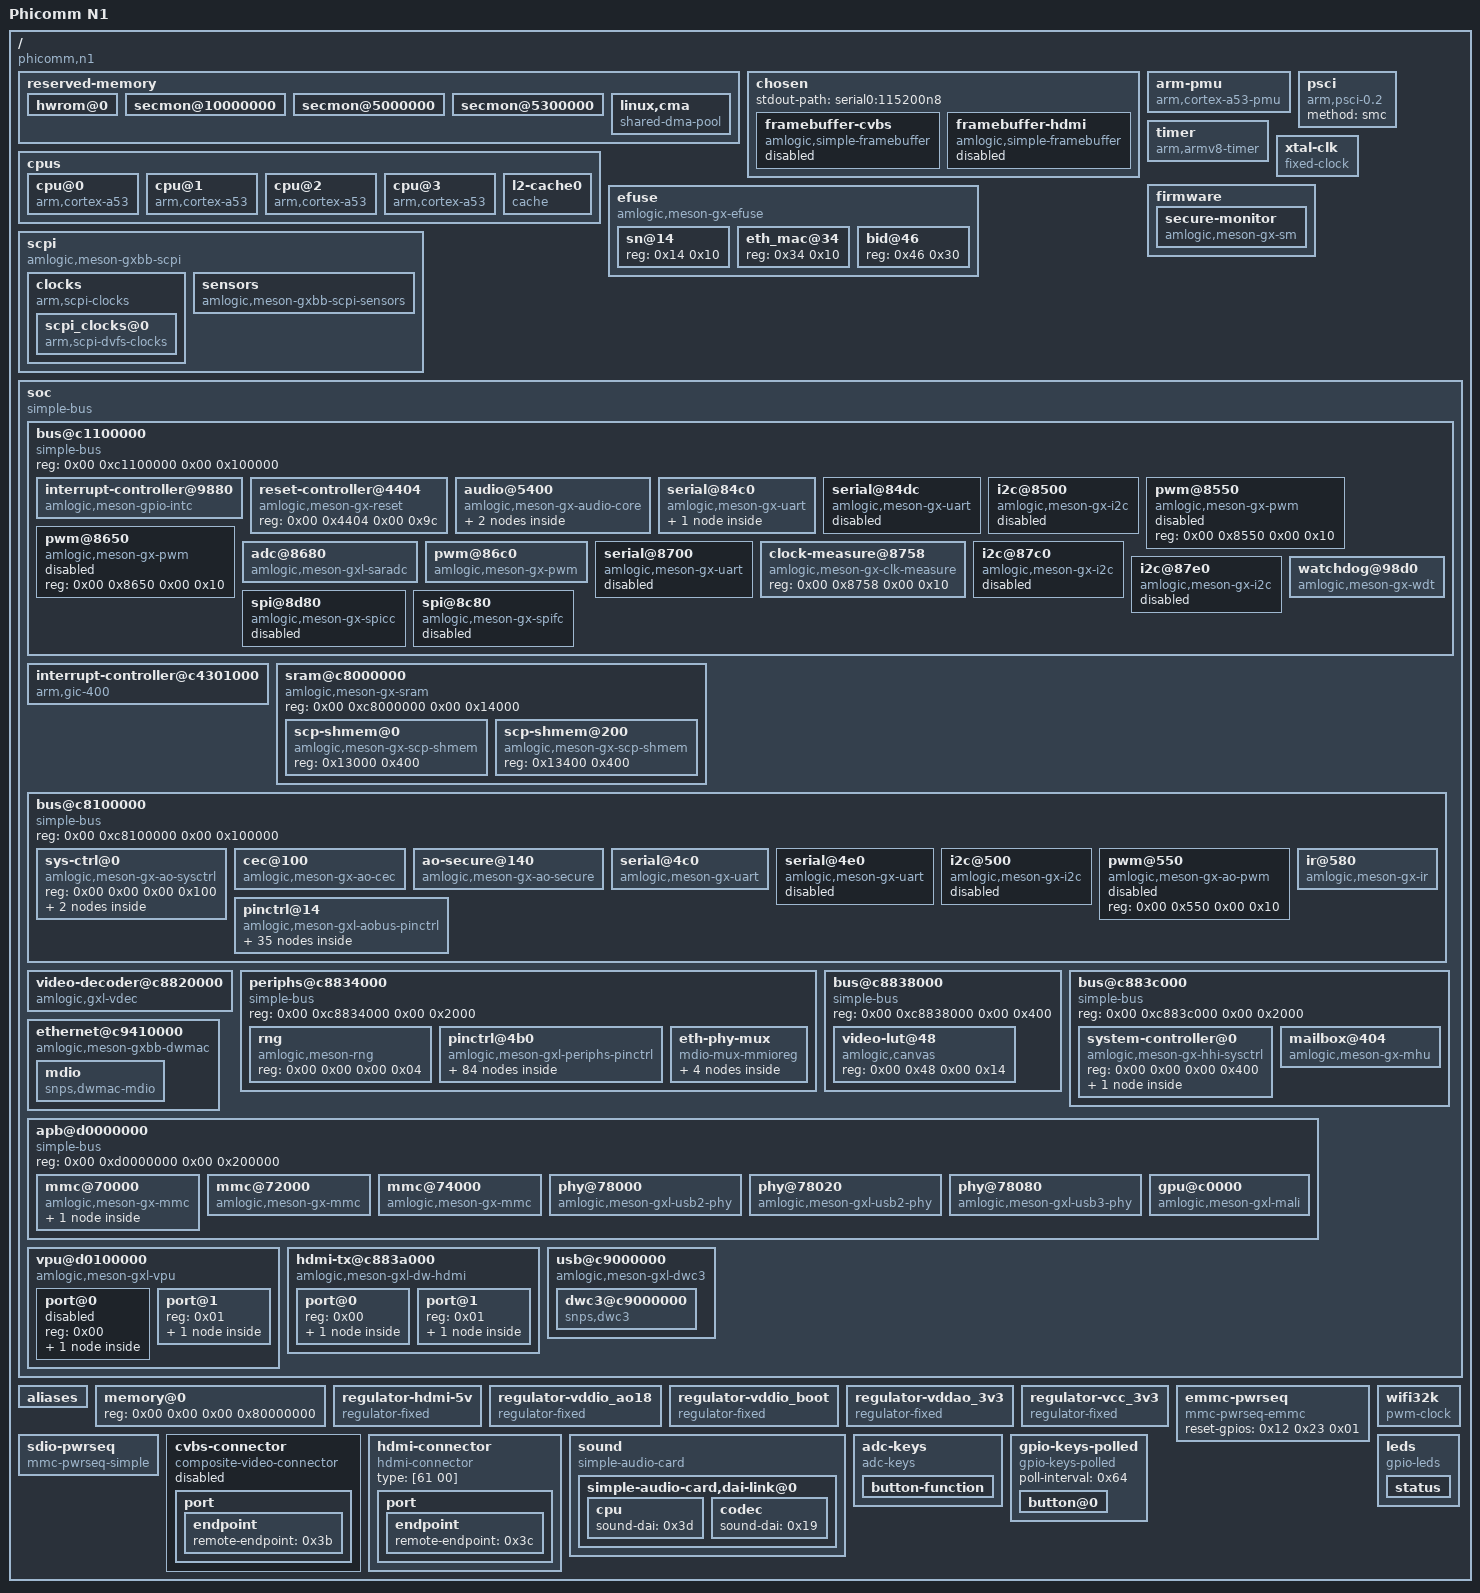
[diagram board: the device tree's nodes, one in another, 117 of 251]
/dts-v1/;

/ {
	interrupt-parent = <0x01>;
	#address-cells = <0x02>;
	#size-cells = <0x02>;
	compatible = "phicomm,n1\0amlogic,s905d\0amlogic,meson-gxl";
	model = "Phicomm N1";

	reserved-memory {
		#address-cells = <0x02>;
		#size-cells = <0x02>;
		ranges;

		hwrom@0 {
			reg = <0x00 0x00 0x00 0x1000000>;
			no-map;
		};

		secmon@10000000 {
			reg = <0x00 0x10000000 0x00 0x200000>;
			no-map;
		};

		secmon@5000000 {
			reg = <0x00 0x5000000 0x00 0x300000>;
			no-map;
		};

		secmon@5300000 {
			reg = <0x00 0x5300000 0x00 0x2000000>;
			no-map;
		};

		linux,cma {
			compatible = "shared-dma-pool";
			reusable;
			size = <0x00 0x38000000>;
			alignment = <0x00 0x400000>;
			linux,cma-default;
		};
	};

	chosen {
		#address-cells = <0x02>;
		#size-cells = <0x02>;
		ranges;
		stdout-path = "serial0:115200n8";

		framebuffer-cvbs {
			compatible = "amlogic,simple-framebuffer\0simple-framebuffer";
			amlogic,pipeline = "vpu-cvbs";
			power-domains = <0x02>;
			status = "disabled";
		};

		framebuffer-hdmi {
			compatible = "amlogic,simple-framebuffer\0simple-framebuffer";
			amlogic,pipeline = "vpu-hdmi";
			power-domains = <0x02>;
			status = "disabled";
			clocks = <0x03 0x3f 0x03 0x0c 0x03 0x4d>;
		};
	};

	cpus {
		#address-cells = <0x02>;
		#size-cells = <0x00>;

		cpu@0 {
			device_type = "cpu";
			compatible = "arm,cortex-a53";
			reg = <0x00 0x00>;
			enable-method = "psci";
			next-level-cache = <0x04>;
			clocks = <0x05 0x00>;
			phandle = <0x06>;
		};

		cpu@1 {
			device_type = "cpu";
			compatible = "arm,cortex-a53";
			reg = <0x00 0x01>;
			enable-method = "psci";
			next-level-cache = <0x04>;
			clocks = <0x05 0x00>;
			phandle = <0x07>;
		};

		cpu@2 {
			device_type = "cpu";
			compatible = "arm,cortex-a53";
			reg = <0x00 0x02>;
			enable-method = "psci";
			next-level-cache = <0x04>;
			clocks = <0x05 0x00>;
			phandle = <0x08>;
		};

		cpu@3 {
			device_type = "cpu";
			compatible = "arm,cortex-a53";
			reg = <0x00 0x03>;
			enable-method = "psci";
			next-level-cache = <0x04>;
			clocks = <0x05 0x00>;
			phandle = <0x09>;
		};

		l2-cache0 {
			compatible = "cache";
			phandle = <0x04>;
		};
	};

	arm-pmu {
		compatible = "arm,cortex-a53-pmu";
		interrupts = <0x00 0x89 0x04 0x00 0x8a 0x04 0x00 0x99 0x04 0x00 0x9a 0x04>;
		interrupt-affinity = <0x06 0x07 0x08 0x09>;
	};

	psci {
		compatible = "arm,psci-0.2";
		method = "smc";
	};

	timer {
		compatible = "arm,armv8-timer";
		interrupts = <0x01 0x0d 0xff08 0x01 0x0e 0xff08 0x01 0x0b 0xff08 0x01 0x0a 0xff08>;
	};

	xtal-clk {
		compatible = "fixed-clock";
		clock-frequency = <0x16e3600>;
		clock-output-names = "xtal";
		#clock-cells = <0x00>;
		phandle = <0x0f>;
	};

	firmware {

		secure-monitor {
			compatible = "amlogic,meson-gx-sm\0amlogic,meson-gxbb-sm";
			phandle = <0x0a>;
		};
	};

	efuse {
		compatible = "amlogic,meson-gx-efuse\0amlogic,meson-gxbb-efuse";
		#address-cells = <0x01>;
		#size-cells = <0x01>;
		read-only;
		secure-monitor = <0x0a>;
		clocks = <0x03 0x3a>;

		sn@14 {
			reg = <0x14 0x10>;
		};

		eth_mac@34 {
			reg = <0x34 0x10>;
		};

		bid@46 {
			reg = <0x46 0x30>;
		};
	};

	scpi {
		compatible = "amlogic,meson-gxbb-scpi\0arm,scpi-pre-1.0";
		mboxes = <0x0b 0x01 0x0b 0x02>;
		shmem = <0x0c 0x0d>;

		clocks {
			compatible = "arm,scpi-clocks";

			scpi_clocks@0 {
				compatible = "arm,scpi-dvfs-clocks";
				#clock-cells = <0x01>;
				clock-indices = <0x00>;
				clock-output-names = "vcpu";
				phandle = <0x05>;
			};
		};

		sensors {
			compatible = "amlogic,meson-gxbb-scpi-sensors\0arm,scpi-sensors";
			#thermal-sensor-cells = <0x01>;
		};
	};

	soc {
		compatible = "simple-bus";
		#address-cells = <0x02>;
		#size-cells = <0x02>;
		ranges;

		bus@c1100000 {
			compatible = "simple-bus";
			reg = <0x00 0xc1100000 0x00 0x100000>;
			#address-cells = <0x02>;
			#size-cells = <0x02>;
			ranges = <0x00 0x00 0x00 0xc1100000 0x00 0x100000>;

			interrupt-controller@9880 {
				compatible = "amlogic,meson-gpio-intc\0amlogic,meson-gxl-gpio-intc";
				reg = <0x00 0x9880 0x00 0x10>;
				interrupt-controller;
				#interrupt-cells = <0x02>;
				amlogic,channel-interrupts = <0x40 0x41 0x42 0x43 0x44 0x45 0x46 0x47>;
				status = "okay";
				#phandle = <0x21>;
			};

			reset-controller@4404 {
				compatible = "amlogic,meson-gx-reset\0amlogic,meson-gxbb-reset";
				reg = <0x00 0x4404 0x00 0x9c>;
				#reset-cells = <0x01>;
				phandle = <0x0e>;
			};

			audio@5400 {
				compatible = "amlogic,meson-gx-audio-core";
				reg = <0x00 0x5400 0x00 0x2ac 0x00 0xa000 0x00 0x304>;
				reg-names = "aiu\0audin";
				status = "okay";
				clocks = <0x03 0x2f 0x03 0x26 0x03 0x23>;
				clock-names = "aiu_top\0aiu_glue\0audin";
				resets = <0x0e 0x06 0x0e 0x41>;
				reset-names = "aiu\0audin";

				audio-controller-0 {
					#sound-dai-cells = <0x00>;
					compatible = "amlogic,meson-aiu-i2s";
					interrupts = <0x00 0x30 0x01>;
					status = "okay";
					clocks = <0x03 0x28 0x03 0x2c 0x03 0x50 0x03 0x6b>;
					clock-names = "fast\0iface\0bclks\0mclk";
					phandle = <0x3d>;
				};

				audio-controller-1 {
					#sound-dai-cells = <0x00>;
					compatible = "amlogic,meson-aiu-spdif";
					interrupts = <0x00 0x32 0x01>;
					status = "disabled";
					clocks = <0x03 0x27 0x03 0x51 0x03 0x6e 0x03 0x6b 0x03 0x71>;
					clock-names = "fast\0iface\0mclk_i958\0mclk_i2s\0mclk";
				};
			};

			serial@84c0 {
				compatible = "amlogic,meson-gx-uart";
				reg = <0x00 0x84c0 0x00 0x18>;
				interrupts = <0x00 0x1a 0x01>;
				status = "okay";
				clocks = <0x0f 0x03 0x1a 0x0f>;
				clock-names = "xtal\0pclk\0baud";
				pinctrl-0 = <0x10 0x11>;
				pinctrl-names = "default";
				uart-has-rtscts;

				bluetooth {
					compatible = "brcm,bcm43438-bt";
					shutdown-gpios = <0x12 0x60 0x00>;
					max-speed = <0x1e8480>;
					clocks = <0x13>;
					clock-names = "lpo";
				};
			};

			serial@84dc {
				compatible = "amlogic,meson-gx-uart";
				reg = <0x00 0x84dc 0x00 0x18>;
				interrupts = <0x00 0x4b 0x01>;
				status = "disabled";
				clocks = <0x0f 0x03 0x30 0x0f>;
				clock-names = "xtal\0pclk\0baud";
			};

			i2c@8500 {
				compatible = "amlogic,meson-gx-i2c\0amlogic,meson-gxbb-i2c";
				reg = <0x00 0x8500 0x00 0x20>;
				interrupts = <0x00 0x15 0x01>;
				#address-cells = <0x01>;
				#size-cells = <0x00>;
				status = "disabled";
				clocks = <0x03 0x16>;
			};

			pwm@8550 {
				compatible = "amlogic,meson-gx-pwm\0amlogic,meson-gxbb-pwm";
				reg = <0x00 0x8550 0x00 0x10>;
				#pwm-cells = <0x03>;
				status = "disabled";
			};

			pwm@8650 {
				compatible = "amlogic,meson-gx-pwm\0amlogic,meson-gxbb-pwm";
				reg = <0x00 0x8650 0x00 0x10>;
				#pwm-cells = <0x03>;
				status = "disabled";
			};

			adc@8680 {
				compatible = "amlogic,meson-gxl-saradc\0amlogic,meson-saradc";
				reg = <0x00 0x8680 0x00 0x34>;
				#io-channel-cells = <0x01>;
				interrupts = <0x00 0x49 0x01>;
				status = "okay";
				clocks = <0x0f 0x03 0x17 0x03 0x61 0x03 0x62>;
				clock-names = "clkin\0core\0adc_clk\0adc_sel";
				vref-supply = <0x14>;
				phandle = <0x3e>;
			};

			pwm@86c0 {
				compatible = "amlogic,meson-gx-pwm\0amlogic,meson-gxbb-pwm";
				reg = <0x00 0x86c0 0x00 0x10>;
				#pwm-cells = <0x03>;
				status = "okay";
				pinctrl-0 = <0x15>;
				pinctrl-names = "default";
				clocks = <0x03 0x06>;
				clock-names = "clkin0";
				phandle = <0x3a>;
			};

			serial@8700 {
				compatible = "amlogic,meson-gx-uart";
				reg = <0x00 0x8700 0x00 0x18>;
				interrupts = <0x00 0x5d 0x01>;
				status = "disabled";
				clocks = <0x0f 0x03 0x44 0x0f>;
				clock-names = "xtal\0pclk\0baud";
			};

			clock-measure@8758 {
				compatible = "amlogic,meson-gx-clk-measure";
				reg = <0x00 0x8758 0x00 0x10>;
			};

			i2c@87c0 {
				compatible = "amlogic,meson-gx-i2c\0amlogic,meson-gxbb-i2c";
				reg = <0x00 0x87c0 0x00 0x20>;
				interrupts = <0x00 0xd6 0x01>;
				#address-cells = <0x01>;
				#size-cells = <0x00>;
				status = "disabled";
				clocks = <0x03 0x16>;
			};

			i2c@87e0 {
				compatible = "amlogic,meson-gx-i2c\0amlogic,meson-gxbb-i2c";
				reg = <0x00 0x87e0 0x00 0x20>;
				interrupts = <0x00 0xd7 0x01>;
				#address-cells = <0x01>;
				#size-cells = <0x00>;
				status = "disabled";
				clocks = <0x03 0x16>;
			};

			spi@8d80 {
				compatible = "amlogic,meson-gx-spicc";
				reg = <0x00 0x8d80 0x00 0x80>;
				interrupts = <0x00 0x51 0x04>;
				#address-cells = <0x01>;
				#size-cells = <0x00>;
				status = "disabled";
				clocks = <0x03 0x15>;
				clock-names = "core";
				resets = <0x0e 0xc1>;
				num-cs = <0x01>;
			};

			spi@8c80 {
				compatible = "amlogic,meson-gx-spifc\0amlogic,meson-gxbb-spifc";
				reg = <0x00 0x8c80 0x00 0x80>;
				#address-cells = <0x01>;
				#size-cells = <0x00>;
				status = "disabled";
				clocks = <0x03 0x22>;
			};

			watchdog@98d0 {
				compatible = "amlogic,meson-gx-wdt\0amlogic,meson-gxbb-wdt";
				reg = <0x00 0x98d0 0x00 0x10>;
				clocks = <0x0f>;
			};
		};

		interrupt-controller@c4301000 {
			compatible = "arm,gic-400";
			reg = <0x00 0xc4301000 0x00 0x1000 0x00 0xc4302000 0x00 0x2000 0x00 0xc4304000 0x00 0x2000 0x00 0xc4306000 0x00 0x2000>;
			interrupt-controller;
			interrupts = <0x01 0x09 0xff04>;
			#interrupt-cells = <0x03>;
			#address-cells = <0x00>;
			phandle = <0x01>;
		};

		sram@c8000000 {
			compatible = "amlogic,meson-gx-sram\0amlogic,meson-gxbb-sram\0mmio-sram";
			reg = <0x00 0xc8000000 0x00 0x14000>;
			#address-cells = <0x01>;
			#size-cells = <0x01>;
			ranges = <0x00 0x00 0xc8000000 0x14000>;

			scp-shmem@0 {
				compatible = "amlogic,meson-gx-scp-shmem\0amlogic,meson-gxbb-scp-shmem";
				reg = <0x13000 0x400>;
				phandle = <0x0c>;
			};

			scp-shmem@200 {
				compatible = "amlogic,meson-gx-scp-shmem\0amlogic,meson-gxbb-scp-shmem";
				reg = <0x13400 0x400>;
				phandle = <0x0d>;
			};
		};

		bus@c8100000 {
			compatible = "simple-bus";
			reg = <0x00 0xc8100000 0x00 0x100000>;
			#address-cells = <0x02>;
			#size-cells = <0x02>;
			ranges = <0x00 0x00 0x00 0xc8100000 0x00 0x100000>;

			sys-ctrl@0 {
				compatible = "amlogic,meson-gx-ao-sysctrl\0simple-mfd\0syscon";
				reg = <0x00 0x00 0x00 0x100>;
				phandle = <0x1d>;

				power-controller-vpu {
					compatible = "amlogic,meson-gx-pwrc-vpu";
					#power-domain-cells = <0x00>;
					amlogic,hhi-sysctrl = <0x16>;
					resets = <0x0e 0x05 0x0e 0x0a 0x0e 0x0d 0x0e 0x25 0x0e 0x84 0x0e 0x85 0x0e 0x86 0x0e 0x87 0x0e 0x89 0x0e 0x8c 0x0e 0x8d 0x0e 0xe7>;
					clocks = <0x03 0x84 0x03 0x8c>;
					clock-names = "vpu\0vapb";
					assigned-clocks = <0x03 0x7e 0x03 0x80 0x03 0x84 0x03 0x85 0x03 0x87 0x03 0x8b>;
					assigned-clock-parents = <0x03 0x05 0x00 0x03 0x80 0x03 0x06 0x00 0x03 0x87>;
					assigned-clock-rates = <0x00 0x27bc86aa 0x00 0x00 0xee6b280 0x00>;
					phandle = <0x02>;
				};

				clock-controller {
					compatible = "amlogic,meson-gxl-aoclkc\0amlogic,meson-gx-aoclkc";
					#clock-cells = <0x01>;
					#reset-cells = <0x01>;
					clocks = <0x0f 0x03 0x0c>;
					clock-names = "xtal\0mpeg-clk";
					phandle = <0x17>;
				};
			};

			cec@100 {
				compatible = "amlogic,meson-gx-ao-cec";
				reg = <0x00 0x100 0x00 0x14>;
				interrupts = <0x00 0xc7 0x01>;
				clocks = <0x17 0x06>;
				clock-names = "core";
				status = "okay";
				pinctrl-0 = <0x18>;
				pinctrl-names = "default";
				hdmi-phandle = <0x19>;
			};

			ao-secure@140 {
				compatible = "amlogic,meson-gx-ao-secure\0syscon";
				reg = <0x00 0x140 0x00 0x140>;
				amlogic,has-chip-id;
			};

			serial@4c0 {
				compatible = "amlogic,meson-gx-uart\0amlogic,meson-ao-uart";
				reg = <0x00 0x4c0 0x00 0x18>;
				interrupts = <0x00 0xc1 0x01>;
				status = "okay";
				clocks = <0x0f 0x17 0x03 0x0f>;
				clock-names = "xtal\0pclk\0baud";
				pinctrl-0 = <0x1a>;
				pinctrl-names = "default";
			};

			serial@4e0 {
				compatible = "amlogic,meson-gx-uart\0amlogic,meson-ao-uart";
				reg = <0x00 0x4e0 0x00 0x18>;
				interrupts = <0x00 0xc5 0x01>;
				status = "disabled";
				clocks = <0x0f 0x17 0x04 0x0f>;
				clock-names = "xtal\0pclk\0baud";
			};

			i2c@500 {
				compatible = "amlogic,meson-gx-i2c\0amlogic,meson-gxbb-i2c";
				reg = <0x00 0x500 0x00 0x20>;
				interrupts = <0x00 0xc3 0x01>;
				#address-cells = <0x01>;
				#size-cells = <0x00>;
				status = "disabled";
				clocks = <0x03 0x5d>;
			};

			pwm@550 {
				compatible = "amlogic,meson-gx-ao-pwm\0amlogic,meson-gxbb-ao-pwm";
				reg = <0x00 0x550 0x00 0x10>;
				#pwm-cells = <0x03>;
				status = "disabled";
			};

			ir@580 {
				compatible = "amlogic,meson-gx-ir\0amlogic,meson-gxbb-ir";
				reg = <0x00 0x580 0x00 0x40>;
				interrupts = <0x00 0xc4 0x01>;
				status = "okay";
				pinctrl-0 = <0x1b>;
				pinctrl-names = "default";
				linux,rc-map-name = "rc-geekbox";
			};

			pinctrl@14 {
				compatible = "amlogic,meson-gxl-aobus-pinctrl";
				#address-cells = <0x02>;
				#size-cells = <0x02>;
				ranges;
				phandle = <0x1c>;

				bank@14 {
					reg = <0x00 0x14 0x00 0x08 0x00 0x2c 0x00 0x04 0x00 0x24 0x00 0x08>;
					reg-names = "mux\0pull\0gpio";
					gpio-controller;
					#gpio-cells = <0x02>;
					gpio-ranges = <0x1c 0x00 0x00 0x0e>;
					phandle = <0x3f>;
				};

				uart_ao_a {
					phandle = <0x1a>;

					mux {
						groups = "uart_tx_ao_a\0uart_rx_ao_a";
						function = "uart_ao";
						bias-disable;
					};
				};

				uart_ao_a_cts_rts {

					mux {
						groups = "uart_cts_ao_a\0uart_rts_ao_a";
						function = "uart_ao";
						bias-disable;
					};
				};

				uart_ao_b {

					mux {
						groups = "uart_tx_ao_b\0uart_rx_ao_b";
						function = "uart_ao_b";
						bias-disable;
					};
				};

				uart_ao_b_0_1 {

					mux {
						groups = "uart_tx_ao_b_0\0uart_rx_ao_b_1";
						function = "uart_ao_b";
						bias-disable;
					};
				};

				uart_ao_b_cts_rts {

					mux {
						groups = "uart_cts_ao_b\0uart_rts_ao_b";
						function = "uart_ao_b";
						bias-disable;
					};
				};

				remote_input_ao {
					phandle = <0x1b>;

					mux {
						groups = "remote_input_ao";
						function = "remote_input_ao";
						bias-disable;
					};
				};

				i2c_ao {

					mux {
						groups = "i2c_sck_ao\0i2c_sda_ao";
						function = "i2c_ao";
						bias-disable;
					};
				};

				pwm_ao_a_3 {

					mux {
						groups = "pwm_ao_a_3";
						function = "pwm_ao_a";
						bias-disable;
					};
				};

				pwm_ao_a_8 {

					mux {
						groups = "pwm_ao_a_8";
						function = "pwm_ao_a";
						bias-disable;
					};
				};

				pwm_ao_b {

					mux {
						groups = "pwm_ao_b";
						function = "pwm_ao_b";
						bias-disable;
					};
				};

				pwm_ao_b_6 {

					mux {
						groups = "pwm_ao_b_6";
						function = "pwm_ao_b";
						bias-disable;
					};
				};

				i2s_out_ch23_ao {

					mux {
						groups = "i2s_out_ch23_ao";
						function = "i2s_out_ao";
						bias-disable;
					};
				};

				i2s_out_ch45_ao {

					mux {
						groups = "i2s_out_ch45_ao";
						function = "i2s_out_ao";
						bias-disable;
					};
				};

				spdif_out_ao_6 {

					mux {
						groups = "spdif_out_ao_6";
						function = "spdif_out_ao";
						bias-disable;
					};
				};

				spdif_out_ao_9 {

					mux {
						groups = "spdif_out_ao_9";
						function = "spdif_out_ao";
						bias-disable;
					};
				};

				ao_cec {
					phandle = <0x18>;

					mux {
						groups = "ao_cec";
						function = "cec_ao";
						bias-disable;
					};
				};

				ee_cec {

					mux {
						groups = "ee_cec";
						function = "cec_ao";
						bias-disable;
					};
				};
			};
		};

		video-decoder@c8820000 {
			compatible = "amlogic,gxl-vdec";
			reg = <0x00 0xc8820000 0x00 0x10000 0x00 0xc110a580 0x00 0xe4>;
			reg-names = "dos\0esparser";
			interrupts = <0x00 0x2c 0x01 0x00 0x20 0x01>;
			interrupt-names = "vdec\0esparser";
			amlogic,ao-sysctrl = <0x1d>;
			amlogic,canvas = <0x1e>;
			clocks = <0x03 0x36 0x03 0x11 0x03 0x99 0x03 0x9c>;
			clock-names = "dos_parser\0dos\0vdec_1\0vdec_hevc";
			resets = <0x0e 0x28>;
			reset-names = "esparser";
		};

		periphs@c8834000 {
			compatible = "simple-bus";
			reg = <0x00 0xc8834000 0x00 0x2000>;
			#address-cells = <0x02>;
			#size-cells = <0x02>;
			ranges = <0x00 0x00 0x00 0xc8834000 0x00 0x2000>;

			rng {
				compatible = "amlogic,meson-rng";
				reg = <0x00 0x00 0x00 0x04>;
			};

			pinctrl@4b0 {
				compatible = "amlogic,meson-gxl-periphs-pinctrl";
				#address-cells = <0x02>;
				#size-cells = <0x02>;
				ranges;
				phandle = <0x1f>;

				bank@4b0 {
					reg = <0x00 0x4b0 0x00 0x28 0x00 0x4e8 0x00 0x14 0x00 0x520 0x00 0x14 0x00 0x430 0x00 0x40>;
					reg-names = "mux\0pull\0pull-enable\0gpio";
					gpio-controller;
					#gpio-cells = <0x02>;
					gpio-ranges = <0x1f 0x00 0x00 0x64>;
					phandle = <0x12>;
				};

				emmc {
					phandle = <0x2b>;

					mux-0 {
						groups = "emmc_nand_d07\0emmc_cmd";
						function = "emmc";
						bias-pull-up;
					};

					mux-1 {
						groups = "emmc_clk";
						function = "emmc";
						bias-disable;
					};
				};

				emmc-ds {
					phandle = <0x2c>;

					mux {
						groups = "emmc_ds";
						function = "emmc";
						bias-pull-down;
					};
				};

				emmc_clk_gate {
					phandle = <0x2d>;

					mux {
						groups = "BOOT_8";
						function = "gpio_periphs";
						bias-pull-down;
					};
				};

				nor {

					mux {
						groups = "nor_d\0nor_q\0nor_c\0nor_cs";
						function = "nor";
						bias-disable;
					};
				};

				spi-pins {

					mux {
						groups = "spi_miso\0spi_mosi\0spi_sclk";
						function = "spi";
						bias-disable;
					};
				};

				spi-ss0 {

					mux {
						groups = "spi_ss0";
						function = "spi";
						bias-disable;
					};
				};

				sdcard {
					phandle = <0x29>;

					mux-0 {
						groups = "sdcard_d0\0sdcard_d1\0sdcard_d2\0sdcard_d3\0sdcard_cmd";
						function = "sdcard";
						bias-pull-up;
					};

					mux-1 {
						groups = "sdcard_clk";
						function = "sdcard";
						bias-disable;
					};
				};

				sdcard_clk_gate {
					phandle = <0x2a>;

					mux {
						groups = "CARD_2";
						function = "gpio_periphs";
						bias-pull-down;
					};
				};

				sdio {
					phandle = <0x24>;

					mux-0 {
						groups = "sdio_d0\0sdio_d1\0sdio_d2\0sdio_d3\0sdio_cmd";
						function = "sdio";
						bias-pull-up;
					};

					mux-1 {
						groups = "sdio_clk";
						function = "sdio";
						bias-disable;
					};
				};

				sdio_clk_gate {
					phandle = <0x25>;

					mux {
						groups = "GPIOX_4";
						function = "gpio_periphs";
						bias-pull-down;
					};
				};

				sdio_irq {

					mux {
						groups = "sdio_irq";
						function = "sdio";
						bias-disable;
					};
				};

				uart_a {
					phandle = <0x10>;

					mux {
						groups = "uart_tx_a\0uart_rx_a";
						function = "uart_a";
						bias-disable;
					};
				};

				uart_a_cts_rts {
					phandle = <0x11>;

					mux {
						groups = "uart_cts_a\0uart_rts_a";
						function = "uart_a";
						bias-disable;
					};
				};

				uart_b {

					mux {
						groups = "uart_tx_b\0uart_rx_b";
						function = "uart_b";
						bias-disable;
					};
				};

				uart_b_cts_rts {

					mux {
						groups = "uart_cts_b\0uart_rts_b";
						function = "uart_b";
						bias-disable;
					};
				};

				uart_c {

					mux {
						groups = "uart_tx_c\0uart_rx_c";
						function = "uart_c";
						bias-disable;
					};
				};

				uart_c_cts_rts {

					mux {
						groups = "uart_cts_c\0uart_rts_c";
						function = "uart_c";
						bias-disable;
					};
				};

				i2c_a {

					mux {
						groups = "i2c_sck_a\0i2c_sda_a";
						function = "i2c_a";
						bias-disable;
					};
				};

				i2c_b {

					mux {
						groups = "i2c_sck_b\0i2c_sda_b";
						function = "i2c_b";
						bias-disable;
					};
				};

				i2c_c {

					mux {
						groups = "i2c_sck_c\0i2c_sda_c";
						function = "i2c_c";
						bias-disable;
					};
				};

				eth_c {
					phandle = <0x22>;

					mux {
						groups = "eth_mdio\0eth_mdc\0eth_clk_rx_clk\0eth_rx_dv\0eth_rxd0\0eth_rxd1\0eth_rxd2\0eth_rxd3\0eth_rgmii_tx_clk\0eth_tx_en\0eth_txd0\0eth_txd1\0eth_txd2\0eth_txd3";
						function = "eth";
						bias-disable;
					};
				};

				eth_link_led {

					mux {
						groups = "eth_link_led";
						function = "eth_led";
						bias-disable;
					};
				};

				eth_act_led {

					mux {
						groups = "eth_act_led";
						function = "eth_led";
					};
				};

				pwm_a {

					mux {
						groups = "pwm_a";
						function = "pwm_a";
						bias-disable;
					};
				};

				pwm_b {

					mux {
						groups = "pwm_b";
						function = "pwm_b";
						bias-disable;
					};
				};

				pwm_c {

					mux {
						groups = "pwm_c";
						function = "pwm_c";
						bias-disable;
					};
				};

				pwm_d {

					mux {
						groups = "pwm_d";
						function = "pwm_d";
						bias-disable;
					};
				};

				pwm_e {
					phandle = <0x15>;

					mux {
						groups = "pwm_e";
						function = "pwm_e";
						bias-disable;
					};
				};

				pwm_f_clk {

					mux {
						groups = "pwm_f_clk";
						function = "pwm_f";
						bias-disable;
					};
				};

				pwm_f_x {

					mux {
						groups = "pwm_f_x";
						function = "pwm_f";
						bias-disable;
					};
				};

				hdmi_hpd {
					phandle = <0x32>;

					mux {
						groups = "hdmi_hpd";
						function = "hdmi_hpd";
						bias-disable;
					};
				};

				hdmi_i2c {
					phandle = <0x33>;

					mux {
						groups = "hdmi_sda\0hdmi_scl";
						function = "hdmi_i2c";
						bias-disable;
					};
				};

				i2s_am_clk {

					mux {
						groups = "i2s_am_clk";
						function = "i2s_out";
						bias-disable;
					};
				};

				i2s_out_ao_clk {

					mux {
						groups = "i2s_out_ao_clk";
						function = "i2s_out";
						bias-disable;
					};
				};

				i2s_out_lr_clk {

					mux {
						groups = "i2s_out_lr_clk";
						function = "i2s_out";
						bias-disable;
					};
				};

				i2s_out_ch01 {

					mux {
						groups = "i2s_out_ch01";
						function = "i2s_out";
						bias-disable;
					};
				};

				i2sout_ch23_z {

					mux {
						groups = "i2sout_ch23_z";
						function = "i2s_out";
						bias-disable;
					};
				};

				i2sout_ch45_z {

					mux {
						groups = "i2sout_ch45_z";
						function = "i2s_out";
						bias-disable;
					};
				};

				i2sout_ch67_z {

					mux {
						groups = "i2sout_ch67_z";
						function = "i2s_out";
						bias-disable;
					};
				};

				spdif_out_ao_h {

					mux {
						groups = "spdif_out_h";
						function = "spdif_out";
						bias-disable;
					};
				};
			};

			eth-phy-mux {
				compatible = "mdio-mux-mmioreg\0mdio-mux";
				#address-cells = <0x01>;
				#size-cells = <0x00>;
				reg = <0x00 0x55c 0x00 0x04>;
				mux-mask = <0xffffffff>;
				mdio-parent-bus = <0x20>;

				mdio@e40908ff {
					reg = <0xe40908ff>;
					#address-cells = <0x01>;
					#size-cells = <0x00>;

					ethernet-phy@8 {
						compatible = "ethernet-phy-id0181.4400\0ethernet-phy-ieee802.3-c22";
						interrupts = <0x00 0x09 0x04>;
						reg = <0x08>;
						max-speed = <0x64>;
					};
				};

				mdio@2009087f {
					reg = <0x2009087f>;
					#address-cells = <0x01>;
					#size-cells = <0x00>;

					ethernet-phy@0 {
						reg = <0x00>;
						max-speed = <0x3e8>;
						reset-assert-us = <0x2710>;
						reset-deassert-us = <0x7530>;
						reset-gpios = <0x12 0x0e 0x01>;
						interrupt-parent = <0x21>;
						interrupts = <0x1d 0x08>;
						eee-broken-1000t;
						phandle = <0x23>;
					};
				};
			};
		};

		bus@c8838000 {
			compatible = "simple-bus";
			reg = <0x00 0xc8838000 0x00 0x400>;
			#address-cells = <0x02>;
			#size-cells = <0x02>;
			ranges = <0x00 0x00 0x00 0xc8838000 0x00 0x400>;

			video-lut@48 {
				compatible = "amlogic,canvas";
				reg = <0x00 0x48 0x00 0x14>;
				phandle = <0x1e>;
			};
		};

		bus@c883c000 {
			compatible = "simple-bus";
			reg = <0x00 0xc883c000 0x00 0x2000>;
			#address-cells = <0x02>;
			#size-cells = <0x02>;
			ranges = <0x00 0x00 0x00 0xc883c000 0x00 0x2000>;

			system-controller@0 {
				compatible = "amlogic,meson-gx-hhi-sysctrl\0simple-mfd\0syscon";
				reg = <0x00 0x00 0x00 0x400>;
				phandle = <0x16>;

				clock-controller {
					compatible = "amlogic,gxl-clkc";
					#clock-cells = <0x01>;
					clocks = <0x0f>;
					clock-names = "xtal";
					phandle = <0x03>;
				};
			};

			mailbox@404 {
				compatible = "amlogic,meson-gx-mhu\0amlogic,meson-gxbb-mhu";
				reg = <0x00 0x404 0x00 0x4c>;
				interrupts = <0x00 0xd0 0x01 0x00 0xd1 0x01 0x00 0xd2 0x01>;
				#mbox-cells = <0x01>;
				phandle = <0x0b>;
			};
		};

		ethernet@c9410000 {
			compatible = "amlogic,meson-gxbb-dwmac\0snps,dwmac-3.70a\0snps,dwmac";
			reg = <0x00 0xc9410000 0x00 0x10000 0x00 0xc8834540 0x00 0x04>;
			interrupts = <0x00 0x08 0x04>;
			interrupt-names = "macirq";
			rx-fifo-depth = <0x1000>;
			tx-fifo-depth = <0x800>;
			status = "okay";
			clocks = <0x03 0x24 0x03 0x04 0x03 0x0f>;
			clock-names = "stmmaceth\0clkin0\0clkin1";
			pinctrl-0 = <0x22>;
			pinctrl-names = "default";
			phy-handle = <0x23>;
			amlogic,tx-delay-ns = <0x02>;
			phy-mode = "rgmii";

			mdio {
				#address-cells = <0x01>;
				#size-cells = <0x00>;
				compatible = "snps,dwmac-mdio";
				phandle = <0x20>;
			};
		};

		apb@d0000000 {
			compatible = "simple-bus";
			reg = <0x00 0xd0000000 0x00 0x200000>;
			#address-cells = <0x02>;
			#size-cells = <0x02>;
			ranges = <0x00 0x00 0x00 0xd0000000 0x00 0x200000>;

			mmc@70000 {
				compatible = "amlogic,meson-gx-mmc\0amlogic,meson-gxbb-mmc";
				reg = <0x00 0x70000 0x00 0x800>;
				interrupts = <0x00 0xd8 0x01>;
				status = "okay";
				clocks = <0x03 0x5e 0x03 0x77 0x03 0x04>;
				clock-names = "core\0clkin0\0clkin1";
				resets = <0x0e 0x2c>;
				pinctrl-0 = <0x24>;
				pinctrl-1 = <0x25>;
				pinctrl-names = "default\0clk-gate";
				#address-cells = <0x01>;
				#size-cells = <0x00>;
				bus-width = <0x04>;
				cap-sd-highspeed;
				max-frequency = <0x5f5e100>;
				non-removable;
				disable-wp;
				mmc-pwrseq = <0x26>;
				vmmc-supply = <0x27>;
				vqmmc-supply = <0x28>;

				wifi@1 {
					reg = <0x01>;
					compatible = "brcm,bcm4329-fmac";
				};
			};

			mmc@72000 {
				compatible = "amlogic,meson-gx-mmc\0amlogic,meson-gxbb-mmc";
				reg = <0x00 0x72000 0x00 0x800>;
				interrupts = <0x00 0xd9 0x01>;
				status = "okay";
				clocks = <0x03 0x5f 0x03 0x7a 0x03 0x04>;
				clock-names = "core\0clkin0\0clkin1";
				resets = <0x0e 0x2d>;
				pinctrl-0 = <0x29>;
				pinctrl-1 = <0x2a>;
				pinctrl-names = "default\0clk-gate";
				bus-width = <0x04>;
				cap-sd-highspeed;
				max-frequency = <0x2faf080>;
				disable-wp;
				cd-gpios = <0x12 0x30 0x01>;
				vmmc-supply = <0x27>;
				vqmmc-supply = <0x28>;
			};

			mmc@74000 {
				compatible = "amlogic,meson-gx-mmc\0amlogic,meson-gxbb-mmc";
				reg = <0x00 0x74000 0x00 0x800>;
				interrupts = <0x00 0xda 0x01>;
				status = "okay";
				clocks = <0x03 0x60 0x03 0x7d 0x03 0x04>;
				clock-names = "core\0clkin0\0clkin1";
				resets = <0x0e 0x2e>;
				pinctrl-0 = <0x2b 0x2c>;
				pinctrl-1 = <0x2d>;
				pinctrl-names = "default\0clk-gate";
				bus-width = <0x08>;
				cap-mmc-highspeed;
				max-frequency = <0xbebc200>;
				non-removable;
				disable-wp;
				mmc-ddr-1_8v;
				mmc-hs200-1_8v;
				mmc-pwrseq = <0x2e>;
				vmmc-supply = <0x2f>;
				vqmmc-supply = <0x28>;
			};

			phy@78000 {
				compatible = "amlogic,meson-gxl-usb2-phy";
				#phy-cells = <0x00>;
				reg = <0x00 0x78000 0x00 0x20>;
				clocks = <0x03 0x37>;
				clock-names = "phy";
				resets = <0x0e 0x22>;
				reset-names = "phy";
				status = "okay";
				phandle = <0x38>;
			};

			phy@78020 {
				compatible = "amlogic,meson-gxl-usb2-phy";
				#phy-cells = <0x00>;
				reg = <0x00 0x78020 0x00 0x20>;
				clocks = <0x03 0x37>;
				clock-names = "phy";
				resets = <0x0e 0x22>;
				reset-names = "phy";
				status = "okay";
				phandle = <0x39>;
			};

			phy@78080 {
				compatible = "amlogic,meson-gxl-usb3-phy";
				#phy-cells = <0x00>;
				reg = <0x00 0x78080 0x00 0x20>;
				interrupts = <0x00 0x10 0x04>;
				clocks = <0x03 0x37 0x17 0x06>;
				clock-names = "phy\0peripheral";
				resets = <0x0e 0x22 0x0e 0x22>;
				reset-names = "phy\0peripheral";
				status = "okay";
				phandle = <0x37>;
			};

			gpu@c0000 {
				compatible = "amlogic,meson-gxl-mali\0arm,mali-450";
				reg = <0x00 0xc0000 0x00 0x40000>;
				interrupts = <0x00 0xa0 0x04 0x00 0xa1 0x04 0x00 0xa2 0x04 0x00 0xa3 0x04 0x00 0xa4 0x04 0x00 0xa5 0x04 0x00 0xa6 0x04 0x00 0xa7 0x04 0x00 0xa8 0x04 0x00 0xa9 0x04>;
				interrupt-names = "gp\0gpmmu\0pp\0pmu\0pp0\0ppmmu0\0pp1\0ppmmu1\0pp2\0ppmmu2";
				clocks = <0x03 0x0c 0x03 0x6a>;
				clock-names = "bus\0core";
				assigned-clocks = <0x03 0x09 0x03 0x64 0x03 0x66 0x03 0x6a>;
				assigned-clock-parents = <0x00 0x03 0x09 0x00 0x03 0x66>;
				assigned-clock-rates = <0x2c588a00 0x00 0x2c588a00 0x00>;
			};
		};

		vpu@d0100000 {
			compatible = "amlogic,meson-gxl-vpu\0amlogic,meson-gx-vpu";
			reg = <0x00 0xd0100000 0x00 0x100000 0x00 0xc883c000 0x00 0x1000 0x00 0xc8838000 0x00 0x1000>;
			reg-names = "vpu\0hhi\0dmc";
			interrupts = <0x00 0x03 0x01>;
			#address-cells = <0x01>;
			#size-cells = <0x00>;
			amlogic,canvas = <0x1e>;
			power-domains = <0x02>;

			port@0 {
				reg = <0x00>;
				status = "disabled";

				endpoint {
					remote-endpoint = <0x30>;
					phandle = <0x3b>;
				};
			};

			port@1 {
				reg = <0x01>;

				endpoint {
					remote-endpoint = <0x31>;
					phandle = <0x35>;
				};
			};
		};

		hdmi-tx@c883a000 {
			compatible = "amlogic,meson-gxl-dw-hdmi\0amlogic,meson-gx-dw-hdmi";
			reg = <0x00 0xc883a000 0x00 0x1c>;
			interrupts = <0x00 0x39 0x01>;
			#address-cells = <0x01>;
			#size-cells = <0x00>;
			status = "okay";
			resets = <0x0e 0x13 0x0e 0x4f 0x0e 0x42>;
			reset-names = "hdmitx_apb\0hdmitx\0hdmitx_phy";
			clocks = <0x03 0x3f 0x03 0x0c 0x03 0x4d>;
			clock-names = "isfr\0iahb\0venci";
			#sound-dai-cells = <0x00>;
			pinctrl-0 = <0x32 0x33>;
			pinctrl-names = "default";
			hdmi-supply = <0x34>;
			phandle = <0x19>;

			port@0 {
				reg = <0x00>;

				endpoint {
					remote-endpoint = <0x35>;
					phandle = <0x31>;
				};
			};

			port@1 {
				reg = <0x01>;

				endpoint {
					remote-endpoint = <0x36>;
					phandle = <0x3c>;
				};
			};
		};

		usb@c9000000 {
			status = "okay";
			compatible = "amlogic,meson-gxl-dwc3";
			#address-cells = <0x02>;
			#size-cells = <0x02>;
			ranges;
			clocks = <0x03 0x37>;
			clock-names = "usb_general";
			resets = <0x0e 0x22>;
			reset-names = "usb_otg";

			dwc3@c9000000 {
				compatible = "snps,dwc3";
				reg = <0x00 0xc9000000 0x00 0x100000>;
				interrupts = <0x00 0x1e 0x04>;
				dr_mode = "host";
				maximum-speed = "high-speed";
				snps,dis_u2_susphy_quirk;
				phys = <0x37 0x38 0x39>;
			};
		};
	};

	aliases {
		serial0 = "/soc/bus@c8100000/serial@4c0";
		ethernet0 = "/soc/ethernet@c9410000";
	};

	memory@0 {
		device_type = "memory";
		reg = <0x00 0x00 0x00 0x80000000>;
	};

	regulator-hdmi-5v {
		compatible = "regulator-fixed";
		regulator-name = "HDMI_5V";
		regulator-min-microvolt = <0x4c4b40>;
		regulator-max-microvolt = <0x4c4b40>;
		gpio = <0x12 0x13 0x00>;
		enable-active-high;
		regulator-always-on;
		phandle = <0x34>;
	};

	regulator-vddio_ao18 {
		compatible = "regulator-fixed";
		regulator-name = "VDDIO_AO18";
		regulator-min-microvolt = <0x1b7740>;
		regulator-max-microvolt = <0x1b7740>;
		phandle = <0x14>;
	};

	regulator-vddio_boot {
		compatible = "regulator-fixed";
		regulator-name = "VDDIO_BOOT";
		regulator-min-microvolt = <0x1b7740>;
		regulator-max-microvolt = <0x1b7740>;
		phandle = <0x28>;
	};

	regulator-vddao_3v3 {
		compatible = "regulator-fixed";
		regulator-name = "VDDAO_3V3";
		regulator-min-microvolt = <0x325aa0>;
		regulator-max-microvolt = <0x325aa0>;
		phandle = <0x27>;
	};

	regulator-vcc_3v3 {
		compatible = "regulator-fixed";
		regulator-name = "VCC_3V3";
		regulator-min-microvolt = <0x325aa0>;
		regulator-max-microvolt = <0x325aa0>;
		phandle = <0x2f>;
	};

	emmc-pwrseq {
		compatible = "mmc-pwrseq-emmc";
		reset-gpios = <0x12 0x23 0x01>;
		phandle = <0x2e>;
	};

	wifi32k {
		compatible = "pwm-clock";
		#clock-cells = <0x00>;
		clock-frequency = <0x8000>;
		pwms = <0x3a 0x00 0x7736 0x00>;
		phandle = <0x13>;
	};

	sdio-pwrseq {
		compatible = "mmc-pwrseq-simple";
		reset-gpios = <0x12 0x55 0x01>;
		clocks = <0x13>;
		clock-names = "ext_clock";
		phandle = <0x26>;
	};

	cvbs-connector {
		compatible = "composite-video-connector";
		status = "disabled";

		port {

			endpoint {
				remote-endpoint = <0x3b>;
				phandle = <0x30>;
			};
		};
	};

	hdmi-connector {
		compatible = "hdmi-connector";
		type = [61 00];

		port {

			endpoint {
				remote-endpoint = <0x3c>;
				phandle = <0x36>;
			};
		};
	};

	sound {
		compatible = "simple-audio-card";
		simple-audio-card,name = "AMLGX";
		assigned-clocks = <0x03 0x0f 0x03 0x0d 0x03 0x0e>;
		assigned-clock-parents = <0x00 0x00 0x00>;
		assigned-clock-rates = <0x11940000 0x10266000 0x17700000>;

		simple-audio-card,dai-link@0 {
			format = "i2s";
			mclk-fs = <0x100>;
			bitclock-master = <0x3d>;
			frame-master = <0x3d>;

			cpu {
				sound-dai = <0x3d>;
			};

			codec {
				sound-dai = <0x19>;
			};
		};
	};

	adc-keys {
		compatible = "adc-keys";
		io-channels = <0x3e 0x00>;
		io-channel-names = "buttons";
		keyup-threshold-microvolt = <0x1a17b0>;

		button-function {
			label = "Update";
			linux,code = <0x168>;
			press-threshold-microvolt = <0x2710>;
		};
	};

	gpio-keys-polled {
		compatible = "gpio-keys-polled";
		#address-cells = <0x01>;
		#size-cells = <0x00>;
		poll-interval = <0x64>;

		button@0 {
			label = "power";
			linux,code = <0x74>;
			gpios = <0x3f 0x02 0x01>;
		};
	};

	leds {
		compatible = "gpio-leds";

		status {
			label = "n1:white:status";
			gpios = <0x3f 0x09 0x00>;
			default-state = "on";
		};
	};
};
